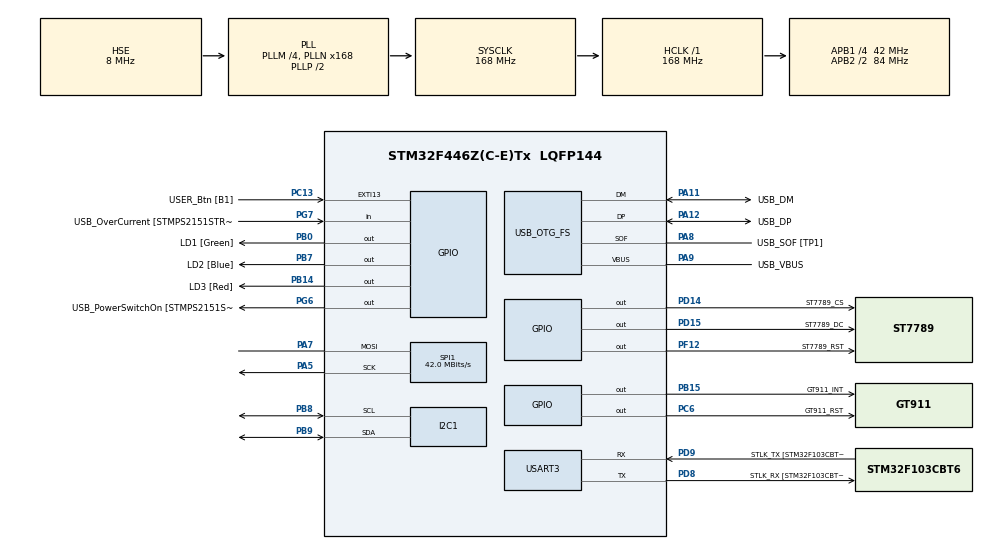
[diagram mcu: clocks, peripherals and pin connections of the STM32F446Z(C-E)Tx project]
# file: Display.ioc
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Dma.Request0=SPI1_TX
Dma.SPI1_TX.0.Direction=DMA_MEMORY_TO_PERIPH
Dma.SPI1_TX.0.FIFOMode=DMA_FIFOMODE_DISABLE
Dma.SPI1_TX.0.Instance=DMA2_Stream3
Dma.SPI1_TX.0.MemDataAlignment=DMA_MDATAALIGN_BYTE
Dma.SPI1_TX.0.MemInc=DMA_MINC_ENABLE
Dma.SPI1_TX.0.Mode=DMA_NORMAL
Dma.SPI1_TX.0.PeriphDataAlignment=DMA_PDATAALIGN_BYTE
Dma.SPI1_TX.0.PeriphInc=DMA_PINC_DISABLE
Dma.SPI1_TX.0.Priority=DMA_PRIORITY_LOW
FREERTOS.Tasks01=GT911Task,0,128,StartGT911Task,Default,NULL,Dynamic,NULL,NULL;ST7789Task,-3,128,StartST7789Task,Default,NULL,Dynamic,NULL,NULL
FREERTOS.configUSE_NEWLIB_REENTRANT=1
I2C1.I2C_Mode=I2C_Fast
Mcu.Family=STM32F4
Mcu.Name=STM32F446Z(C-E)Tx
Mcu.Package=LQFP144
NVIC.DMA2_Stream3_IRQn=true\:5\:0\:false\:false\:true\:true\:false\:true\:true
NVIC.PriorityGroup=NVIC_PRIORITYGROUP_4
NVIC.TIM1_UP_TIM10_IRQn=true\:15\:0\:false\:false\:true\:false\:false\:true\:true
NVIC.TimeBase=TIM1_UP_TIM10_IRQn
NVIC.TimeBaseIP=TIM1
PA10.GPIO_Label=USB_ID
PA10.Signal=USB_OTG_FS_ID
PA11.GPIO_Label=USB_DM
PA11.Mode=Device_Only
PA11.Signal=USB_OTG_FS_DM
PA12.GPIO_Label=USB_DP
PA12.Mode=Device_Only
PA12.Signal=USB_OTG_FS_DP
PA13.GPIO_Label=TMS
PA13.Mode=Serial_Wire
PA13.Signal=SYS_JTMS-SWDIO
PA14.GPIO_Label=TCK
PA14.Mode=Serial_Wire
PA14.Signal=SYS_JTCK-SWCLK
PA5.Mode=Simplex_Bidirectional_Master
PA5.Signal=SPI1_SCK
PA7.Mode=Simplex_Bidirectional_Master
PA7.Signal=SPI1_MOSI
PA8.GPIO_Label=USB_SOF [TP1]
PA8.Mode=Activate_SOF_FS
PA8.Signal=USB_OTG_FS_SOF
PA9.GPIO_Label=USB_VBUS
PA9.Mode=Activate_VBUS
PA9.Signal=USB_OTG_FS_VBUS
PB0.GPIO_Label=LD1 [Green]
PB0.Signal=GPIO_Output
PB14.GPIO_Label=LD3 [Red]
PB14.Signal=GPIO_Output
PB15.GPIO_Label=GT911_INT
PB15.Signal=GPIO_Output
PB7.GPIO_Label=LD2 [Blue]
PB7.Signal=GPIO_Output
PB8.Mode=I2C
PB8.Signal=I2C1_SCL
PB9.Mode=I2C
PB9.Signal=I2C1_SDA
PC13.GPIO_Label=USER_Btn [B1]
PC13.Signal=GPXTI13
PC14-OSC32_IN.Mode=LSE-External-Oscillator
PC14-OSC32_IN.Signal=RCC_OSC32_IN
PC15-OSC32_OUT.Mode=LSE-External-Oscillator
PC15-OSC32_OUT.Signal=RCC_OSC32_OUT
PC6.GPIO_Label=GT911_RST
PC6.Signal=GPIO_Output
PD14.GPIO_Label=ST7789_CS
PD14.Signal=GPIO_Output
PD15.GPIO_Label=ST7789_DC
PD15.Signal=GPIO_Output
PD8.GPIO_Label=STLK_RX [STM32F103CBT6_PA3]
PD8.Mode=Asynchronous
PD8.Signal=USART3_TX
PD9.GPIO_Label=STLK_TX [STM32F103CBT6_PA2]
PD9.Mode=Asynchronous
PD9.Signal=USART3_RX
PF12.GPIO_Label=ST7789_RST
PF12.Signal=GPIO_Output
PG6.GPIO_Label=USB_PowerSwitchOn [STMPS2151STR_EN]
PG6.Signal=GPIO_Output
PG7.GPIO_Label=USB_OverCurrent [STMPS2151STR_FAULT]
PG7.Signal=GPIO_Input
PH0-OSC_IN.GPIO_Label=MCO [STM32F103CBT6_PA8]
PH0-OSC_IN.Mode=HSE-External-Clock-Source
PH0-OSC_IN.Signal=RCC_OSC_IN
PH1-OSC_OUT.Mode=HSE-External-Clock-Source
PH1-OSC_OUT.Signal=RCC_OSC_OUT
ProjectManager.HeapSize=0x200
ProjectManager.StackSize=0x400
ProjectManager.TargetToolchain=STM32CubeIDE
RCC.48MHZClocksFreq_Value=24000000
RCC.AHBFreq_Value=168000000
RCC.APB1CLKDivider=RCC_HCLK_DIV4
RCC.APB1Freq_Value=42000000
RCC.APB1TimFreq_Value=84000000
RCC.APB2CLKDivider=RCC_HCLK_DIV2
RCC.APB2Freq_Value=84000000
RCC.APB2TimFreq_Value=168000000
RCC.CortexFreq_Value=168000000
RCC.HCLKFreq_Value=168000000
RCC.HSE_VALUE=8000000
RCC.HSI_VALUE=16000000
RCC.PLLM=4
RCC.PLLMUL=RCC_PLL_MUL9
RCC.PLLN=168
RCC.PLLQ=7
RCC.PRESCALERUSB=RCC_USBCLKSOURCE_PLL_DIV1_5
RCC.SYSCLKFreq_VALUE=168000000
RCC.SYSCLKSource=RCC_SYSCLKSOURCE_PLLCLK
RCC.SYSCLKSourceVirtual=RCC_SYSCLKSOURCE_PLLCLK
RCC.USBFreq_Value=48000000
RCC.VCOOutputFreq_Value=336000000
SPI1.BaudRatePrescaler=SPI_BAUDRATEPRESCALER_2
SPI1.CLKPolarity=SPI_POLARITY_HIGH
SPI1.CalculateBaudRate=42.0 MBits/s
SPI1.Direction=SPI_DIRECTION_1LINE
SPI1.Mode=SPI_MODE_MASTER
SPI1.VirtualType=VM_MASTER
USART3.VirtualMode=VM_ASYNC
USB_OTG_FS.VirtualMode=Device_Only
VP_FREERTOS_VS_CMSIS_V1.Mode=CMSIS_V1
VP_SYS_VS_tim1.Mode=TIM1
board=NUCLEO-F446ZE

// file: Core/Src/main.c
/* USER CODE BEGIN Header */
/**
  ******************************************************************************
  * @file           : main.c
  * @brief          : Main program body
  ******************************************************************************
  * @attention
  *
  * Copyright (c) 2023 STMicroelectronics.
  * All rights reserved.
  *
  * This software is licensed under terms that can be found in the LICENSE file
  * in the root directory of this software component.
  * If no LICENSE file comes with this software, it is provided AS-IS.
  *
  ******************************************************************************
  */
/* USER CODE END Header */
#include "main.h"
#include "cmsis_os.h"

I2C_HandleTypeDef hi2c1;

SPI_HandleTypeDef hspi1;
DMA_HandleTypeDef hdma_spi1_tx;

UART_HandleTypeDef huart3;

PCD_HandleTypeDef hpcd_USB_OTG_FS;

osThreadId GT911TaskHandle;
osThreadId ST7789TaskHandle;

void SystemClock_Config(void);
static void MX_GPIO_Init(void);
static void MX_DMA_Init(void);
static void MX_USART3_UART_Init(void);
static void MX_USB_OTG_FS_PCD_Init(void);
static void MX_I2C1_Init(void);
static void MX_SPI1_Init(void);
void StartGT911Task(void const * argument);
void StartST7789Task(void const * argument);

/* USER CODE BEGIN 0 */

GT911_Config_t sampleConfig = {.X_Resolution = 320, .Y_Resolution = 240, .Number_Of_Touch_Support = 1, .ReverseY = false, .ReverseX = false, .SwithX2Y = false, .SoftwareNoiseReduction = true};
TouchCoordinate_t coordinate[5];
uint8_t number;

/* USER CODE END 0 */

int main(void)
{

  /* MCU Configuration--------------------------------------------------------*/

  /* Reset of all peripherals, Initializes the Flash interface and the Systick. */
  HAL_Init();

  /* Configure the system clock */
  SystemClock_Config();

  /* Initialize all configured peripherals */
  MX_GPIO_Init();
  MX_DMA_Init();
  MX_USART3_UART_Init();
  MX_USB_OTG_FS_PCD_Init();
  MX_I2C1_Init();
  MX_SPI1_Init();
  /* USER CODE BEGIN 2 */
  DEBUG_Init();
  /* USER CODE END 2 */

  /* Create the thread(s) */
  /* definition and creation of GT911Task */
  osThreadDef(GT911Task, StartGT911Task, osPriorityNormal, 0, 128);
  GT911TaskHandle = osThreadCreate(osThread(GT911Task), NULL);

  /* definition and creation of ST7789Task */
  osThreadDef(ST7789Task, StartST7789Task, osPriorityIdle, 0, 128);
  ST7789TaskHandle = osThreadCreate(osThread(ST7789Task), NULL);

  /* Start scheduler */
  osKernelStart();

  /* We should never get here as control is now taken by the scheduler */
  /* Infinite loop */
  while (1)
  {

  }
}

void SystemClock_Config(void)
{
  RCC_OscInitTypeDef RCC_OscInitStruct = {0};
  RCC_ClkInitTypeDef RCC_ClkInitStruct = {0};

  /** Configure the main internal regulator output voltage
  */
  __HAL_RCC_PWR_CLK_ENABLE();
  __HAL_PWR_VOLTAGESCALING_CONFIG(PWR_REGULATOR_VOLTAGE_SCALE1);

  /** Initializes the RCC Oscillators according to the specified parameters
  * in the RCC_OscInitTypeDef structure.
  */
  RCC_OscInitStruct.OscillatorType = RCC_OSCILLATORTYPE_HSE;
  RCC_OscInitStruct.HSEState = RCC_HSE_BYPASS;
  RCC_OscInitStruct.PLL.PLLState = RCC_PLL_ON;
  RCC_OscInitStruct.PLL.PLLSource = RCC_PLLSOURCE_HSE;
  RCC_OscInitStruct.PLL.PLLM = 4;
  RCC_OscInitStruct.PLL.PLLN = 168;
  RCC_OscInitStruct.PLL.PLLP = RCC_PLLP_DIV2;
  RCC_OscInitStruct.PLL.PLLQ = 7;
  RCC_OscInitStruct.PLL.PLLR = 2;
  if (HAL_RCC_OscConfig(&RCC_OscInitStruct) != HAL_OK)
  {
    Error_Handler();
  }

  /** Initializes the CPU, AHB and APB buses clocks
  */
  RCC_ClkInitStruct.ClockType = RCC_CLOCKTYPE_HCLK|RCC_CLOCKTYPE_SYSCLK
                              |RCC_CLOCKTYPE_PCLK1|RCC_CLOCKTYPE_PCLK2;
  RCC_ClkInitStruct.SYSCLKSource = RCC_SYSCLKSOURCE_PLLCLK;
  RCC_ClkInitStruct.AHBCLKDivider = RCC_SYSCLK_DIV1;
  RCC_ClkInitStruct.APB1CLKDivider = RCC_HCLK_DIV4;
  RCC_ClkInitStruct.APB2CLKDivider = RCC_HCLK_DIV2;

  if (HAL_RCC_ClockConfig(&RCC_ClkInitStruct, FLASH_LATENCY_5) != HAL_OK)
  {
    Error_Handler();
  }
}

static void MX_I2C1_Init(void)
{

  hi2c1.Instance = I2C1;
  hi2c1.Init.ClockSpeed = 400000;
  hi2c1.Init.DutyCycle = I2C_DUTYCYCLE_2;
  hi2c1.Init.OwnAddress1 = 0;
  hi2c1.Init.AddressingMode = I2C_ADDRESSINGMODE_7BIT;
  hi2c1.Init.DualAddressMode = I2C_DUALADDRESS_DISABLE;
  hi2c1.Init.OwnAddress2 = 0;
  hi2c1.Init.GeneralCallMode = I2C_GENERALCALL_DISABLE;
  hi2c1.Init.NoStretchMode = I2C_NOSTRETCH_DISABLE;
  if (HAL_I2C_Init(&hi2c1) != HAL_OK)
  {
    Error_Handler();
  }

}

static void MX_SPI1_Init(void)
{

  /* SPI1 parameter configuration*/
  hspi1.Instance = SPI1;
  hspi1.Init.Mode = SPI_MODE_MASTER;
  hspi1.Init.Direction = SPI_DIRECTION_1LINE;
  hspi1.Init.DataSize = SPI_DATASIZE_8BIT;
  hspi1.Init.CLKPolarity = SPI_POLARITY_HIGH;
  hspi1.Init.CLKPhase = SPI_PHASE_1EDGE;
  hspi1.Init.NSS = SPI_NSS_SOFT;
  hspi1.Init.BaudRatePrescaler = SPI_BAUDRATEPRESCALER_2;
  hspi1.Init.FirstBit = SPI_FIRSTBIT_MSB;
  hspi1.Init.TIMode = SPI_TIMODE_DISABLE;
  hspi1.Init.CRCCalculation = SPI_CRCCALCULATION_DISABLE;
  hspi1.Init.CRCPolynomial = 10;
  if (HAL_SPI_Init(&hspi1) != HAL_OK)
  {
    Error_Handler();
  }

}

static void MX_USART3_UART_Init(void)
{

  huart3.Instance = USART3;
  huart3.Init.BaudRate = 115200;
  huart3.Init.WordLength = UART_WORDLENGTH_8B;
  huart3.Init.StopBits = UART_STOPBITS_1;
  huart3.Init.Parity = UART_PARITY_NONE;
  huart3.Init.Mode = UART_MODE_TX_RX;
  huart3.Init.HwFlowCtl = UART_HWCONTROL_NONE;
  huart3.Init.OverSampling = UART_OVERSAMPLING_16;
  if (HAL_UART_Init(&huart3) != HAL_OK)
  {
    Error_Handler();
  }

}

static void MX_USB_OTG_FS_PCD_Init(void)
{

  hpcd_USB_OTG_FS.Instance = USB_OTG_FS;
  hpcd_USB_OTG_FS.Init.dev_endpoints = 6;
  hpcd_USB_OTG_FS.Init.speed = PCD_SPEED_FULL;
  hpcd_USB_OTG_FS.Init.dma_enable = DISABLE;
  hpcd_USB_OTG_FS.Init.phy_itface = PCD_PHY_EMBEDDED;
  hpcd_USB_OTG_FS.Init.Sof_enable = ENABLE;
  hpcd_USB_OTG_FS.Init.low_power_enable = DISABLE;
  hpcd_USB_OTG_FS.Init.lpm_enable = DISABLE;
  hpcd_USB_OTG_FS.Init.vbus_sensing_enable = ENABLE;
  hpcd_USB_OTG_FS.Init.use_dedicated_ep1 = DISABLE;
  if (HAL_PCD_Init(&hpcd_USB_OTG_FS) != HAL_OK)
  {
    Error_Handler();
  }

}

static void MX_DMA_Init(void)
{

  /* DMA controller clock enable */
  __HAL_RCC_DMA2_CLK_ENABLE();

  /* DMA interrupt init */
  /* DMA2_Stream3_IRQn interrupt configuration */
  HAL_NVIC_SetPriority(DMA2_Stream3_IRQn, 5, 0);
  HAL_NVIC_EnableIRQ(DMA2_Stream3_IRQn);

}

static void MX_GPIO_Init(void)
{
  GPIO_InitTypeDef GPIO_InitStruct = {0};

  /* GPIO Ports Clock Enable */
  __HAL_RCC_GPIOC_CLK_ENABLE();
  __HAL_RCC_GPIOH_CLK_ENABLE();
  __HAL_RCC_GPIOA_CLK_ENABLE();
  __HAL_RCC_GPIOB_CLK_ENABLE();
  __HAL_RCC_GPIOF_CLK_ENABLE();
  __HAL_RCC_GPIOD_CLK_ENABLE();
  __HAL_RCC_GPIOG_CLK_ENABLE();

  /*Configure GPIO pin Output Level */
  HAL_GPIO_WritePin(GPIOB, LD1_Pin|LD3_Pin|GT911_INT_Pin|LD2_Pin, GPIO_PIN_RESET);

  /*Configure GPIO pin Output Level */
  HAL_GPIO_WritePin(ST7789_RST_GPIO_Port, ST7789_RST_Pin, GPIO_PIN_RESET);

  /*Configure GPIO pin Output Level */
  HAL_GPIO_WritePin(GPIOD, ST7789_CS_Pin|ST7789_DC_Pin, GPIO_PIN_RESET);

  /*Configure GPIO pin Output Level */
  HAL_GPIO_WritePin(USB_PowerSwitchOn_GPIO_Port, USB_PowerSwitchOn_Pin, GPIO_PIN_RESET);

  /*Configure GPIO pin Output Level */
  HAL_GPIO_WritePin(GT911_RST_GPIO_Port, GT911_RST_Pin, GPIO_PIN_RESET);

  /*Configure GPIO pin : USER_Btn_Pin */
  GPIO_InitStruct.Pin = USER_Btn_Pin;
  GPIO_InitStruct.Mode = GPIO_MODE_IT_RISING;
  GPIO_InitStruct.Pull = GPIO_NOPULL;
  HAL_GPIO_Init(USER_Btn_GPIO_Port, &GPIO_InitStruct);

  /*Configure GPIO pins : LD1_Pin LD3_Pin GT911_INT_Pin LD2_Pin */
  GPIO_InitStruct.Pin = LD1_Pin|LD3_Pin|GT911_INT_Pin|LD2_Pin;
  GPIO_InitStruct.Mode = GPIO_MODE_OUTPUT_PP;
  GPIO_InitStruct.Pull = GPIO_NOPULL;
  GPIO_InitStruct.Speed = GPIO_SPEED_FREQ_LOW;
  HAL_GPIO_Init(GPIOB, &GPIO_InitStruct);

  /*Configure GPIO pin : ST7789_RST_Pin */
  GPIO_InitStruct.Pin = ST7789_RST_Pin;
  GPIO_InitStruct.Mode = GPIO_MODE_OUTPUT_PP;
  GPIO_InitStruct.Pull = GPIO_NOPULL;
  GPIO_InitStruct.Speed = GPIO_SPEED_FREQ_LOW;
  HAL_GPIO_Init(ST7789_RST_GPIO_Port, &GPIO_InitStruct);

  /*Configure GPIO pins : ST7789_CS_Pin ST7789_DC_Pin */
  GPIO_InitStruct.Pin = ST7789_CS_Pin|ST7789_DC_Pin;
  GPIO_InitStruct.Mode = GPIO_MODE_OUTPUT_PP;
  GPIO_InitStruct.Pull = GPIO_NOPULL;
  GPIO_InitStruct.Speed = GPIO_SPEED_FREQ_LOW;
  HAL_GPIO_Init(GPIOD, &GPIO_InitStruct);

  /*Configure GPIO pin : USB_PowerSwitchOn_Pin */
  GPIO_InitStruct.Pin = USB_PowerSwitchOn_Pin;
  GPIO_InitStruct.Mode = GPIO_MODE_OUTPUT_PP;
  GPIO_InitStruct.Pull = GPIO_NOPULL;
  GPIO_InitStruct.Speed = GPIO_SPEED_FREQ_LOW;
  HAL_GPIO_Init(USB_PowerSwitchOn_GPIO_Port, &GPIO_InitStruct);

  /*Configure GPIO pin : USB_OverCurrent_Pin */
  GPIO_InitStruct.Pin = USB_OverCurrent_Pin;
  GPIO_InitStruct.Mode = GPIO_MODE_INPUT;
  GPIO_InitStruct.Pull = GPIO_NOPULL;
  HAL_GPIO_Init(USB_OverCurrent_GPIO_Port, &GPIO_InitStruct);

  /*Configure GPIO pin : GT911_RST_Pin */
  GPIO_InitStruct.Pin = GT911_RST_Pin;
  GPIO_InitStruct.Mode = GPIO_MODE_OUTPUT_PP;
  GPIO_InitStruct.Pull = GPIO_NOPULL;
  GPIO_InitStruct.Speed = GPIO_SPEED_FREQ_LOW;
  HAL_GPIO_Init(GT911_RST_GPIO_Port, &GPIO_InitStruct);

}

void StartGT911Task(void const * argument)
{
  /* USER CODE BEGIN 5 */

  int i = 0;
  GT911_Init(sampleConfig);

  /* Infinite loop */
  for(;;)
  {
    GT911_ReadTouch(coordinate, &number);
    for (i=0; i<number; ++i)
    	DEBUG_Printf("%d\n%d\r\n\n", coordinate[i].x, coordinate[i].y);
    osDelay(1);
  }
  /* USER CODE END 5 */
}

void StartST7789Task(void const * argument)
{
  /* USER CODE BEGIN StartST7789Task */

  ST7789_Init();

  /* Infinite loop */
  for(;;)
  {
	ST7789_Test();
    osDelay(1);
  }
  /* USER CODE END StartST7789Task */
}

void HAL_TIM_PeriodElapsedCallback(TIM_HandleTypeDef *htim)
{
  if (htim->Instance == TIM1) {
    HAL_IncTick();
  }
}

void Error_Handler(void)
{
  __disable_irq();
  while (1)
  {
  }
}
